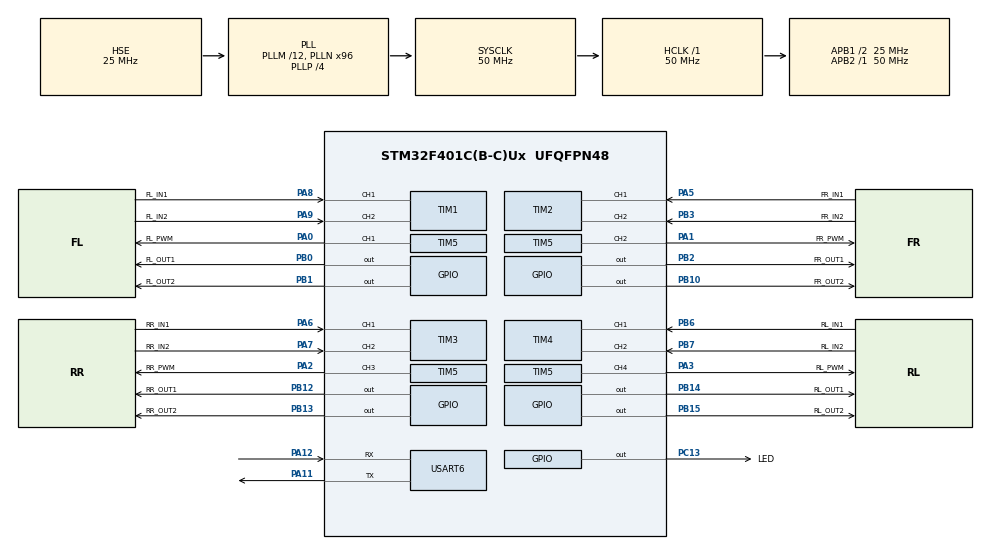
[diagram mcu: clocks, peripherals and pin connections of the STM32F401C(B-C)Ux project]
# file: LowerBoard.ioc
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Dma.Request0=USART6_RX
Dma.Request1=USART6_TX
Dma.USART6_RX.0.Direction=DMA_PERIPH_TO_MEMORY
Dma.USART6_RX.0.FIFOMode=DMA_FIFOMODE_DISABLE
Dma.USART6_RX.0.Instance=DMA2_Stream1
Dma.USART6_RX.0.MemDataAlignment=DMA_MDATAALIGN_BYTE
Dma.USART6_RX.0.MemInc=DMA_MINC_ENABLE
Dma.USART6_RX.0.Mode=DMA_NORMAL
Dma.USART6_RX.0.PeriphDataAlignment=DMA_PDATAALIGN_BYTE
Dma.USART6_RX.0.PeriphInc=DMA_PINC_DISABLE
Dma.USART6_RX.0.Priority=DMA_PRIORITY_LOW
Dma.USART6_TX.1.Direction=DMA_MEMORY_TO_PERIPH
Dma.USART6_TX.1.FIFOMode=DMA_FIFOMODE_DISABLE
Dma.USART6_TX.1.Instance=DMA2_Stream6
Dma.USART6_TX.1.MemDataAlignment=DMA_MDATAALIGN_BYTE
Dma.USART6_TX.1.MemInc=DMA_MINC_ENABLE
Dma.USART6_TX.1.Mode=DMA_NORMAL
Dma.USART6_TX.1.PeriphDataAlignment=DMA_PDATAALIGN_BYTE
Dma.USART6_TX.1.PeriphInc=DMA_PINC_DISABLE
Dma.USART6_TX.1.Priority=DMA_PRIORITY_LOW
Mcu.Family=STM32F4
Mcu.Name=STM32F401C(B-C)Ux
Mcu.Package=UFQFPN48
NVIC.DMA2_Stream1_IRQn=true\:0\:0\:false\:false\:true\:false\:true\:true
NVIC.DMA2_Stream6_IRQn=true\:0\:0\:false\:false\:true\:false\:true\:true
NVIC.PriorityGroup=NVIC_PRIORITYGROUP_4
NVIC.TIM1_TRG_COM_TIM11_IRQn=true\:0\:0\:false\:false\:true\:true\:true\:true
NVIC.TIM1_UP_TIM10_IRQn=true\:0\:0\:false\:false\:true\:true\:true\:true
NVIC.USART6_IRQn=true\:0\:0\:false\:false\:true\:false\:true\:true
PA0-WKUP.GPIO_Label=FL_PWM
PA0-WKUP.GPIO_Speed=GPIO_SPEED_FREQ_HIGH
PA0-WKUP.Signal=S_TIM5_CH1
PA1.GPIO_Label=FR_PWM
PA1.GPIO_Speed=GPIO_SPEED_FREQ_HIGH
PA1.Signal=S_TIM5_CH2
PA11.Mode=Asynchronous
PA11.Signal=USART6_TX
PA12.Mode=Asynchronous
PA12.Signal=USART6_RX
PA13.Mode=Serial_Wire
PA13.Signal=SYS_JTMS-SWDIO
PA14.Mode=Serial_Wire
PA14.Signal=SYS_JTCK-SWCLK
PA2.GPIO_Label=RR_PWM
PA2.GPIO_Speed=GPIO_SPEED_FREQ_HIGH
PA2.Signal=S_TIM5_CH3
PA3.GPIO_Label=RL_PWM
PA3.GPIO_Speed=GPIO_SPEED_FREQ_HIGH
PA3.Signal=S_TIM5_CH4
PA5.GPIO_Label=FR_IN1
PA5.GPIO_PuPd=GPIO_NOPULL
PA5.Signal=S_TIM2_CH1_ETR
PA6.GPIO_Label=RR_IN1
PA6.GPIO_PuPd=GPIO_NOPULL
PA6.Signal=S_TIM3_CH1
PA7.GPIO_Label=RR_IN2
PA7.GPIO_PuPd=GPIO_NOPULL
PA7.Signal=S_TIM3_CH2
PA8.GPIO_Label=FL_IN1
PA8.GPIO_PuPd=GPIO_NOPULL
PA8.Signal=S_TIM1_CH1
PA9.GPIO_Label=FL_IN2
PA9.GPIO_PuPd=GPIO_NOPULL
PA9.Signal=S_TIM1_CH2
PB0.GPIO_Label=FL_OUT1
PB0.Signal=GPIO_Output
PB1.GPIO_Label=FL_OUT2
PB1.Signal=GPIO_Output
PB10.GPIO_Label=FR_OUT2
PB10.Signal=GPIO_Output
PB12.GPIO_Label=RR_OUT1
PB12.Signal=GPIO_Output
PB13.GPIO_Label=RR_OUT2
PB13.Signal=GPIO_Output
PB14.GPIO_Label=RL_OUT1
PB14.Signal=GPIO_Output
PB15.GPIO_Label=RL_OUT2
PB15.Signal=GPIO_Output
PB2.GPIO_Label=FR_OUT1
PB2.Signal=GPIO_Output
PB3.GPIO_Label=FR_IN2
PB3.Signal=S_TIM2_CH2
PB6.GPIO_Label=RL_IN1
PB6.Signal=S_TIM4_CH1
PB7.GPIO_Label=RL_IN2
PB7.Signal=S_TIM4_CH2
PC13-ANTI_TAMP.GPIO_Label=LED
PC13-ANTI_TAMP.GPIO_PuPd=GPIO_NOPULL
PC13-ANTI_TAMP.PinState=GPIO_PIN_SET
PC13-ANTI_TAMP.Signal=GPIO_Output
PH0\ -\ OSC_IN.Mode=HSE-External-Oscillator
PH0\ -\ OSC_IN.Signal=RCC_OSC_IN
PH1\ -\ OSC_OUT.Mode=HSE-External-Oscillator
PH1\ -\ OSC_OUT.Signal=RCC_OSC_OUT
ProjectManager.HeapSize=0x200
ProjectManager.StackSize=0x400
ProjectManager.TargetToolchain=Makefile
RCC.48MHZClocksFreq_Value=50000000
RCC.AHBFreq_Value=50000000
RCC.APB1CLKDivider=RCC_HCLK_DIV2
RCC.APB1Freq_Value=25000000
RCC.APB1TimFreq_Value=50000000
RCC.APB2Freq_Value=50000000
RCC.APB2TimFreq_Value=50000000
RCC.CortexFreq_Value=50000000
RCC.HCLKFreq_Value=50000000
RCC.HSE_VALUE=25000000
RCC.HSI_VALUE=16000000
RCC.LSE_VALUE=32768
RCC.PLLM=12
RCC.PLLN=96
RCC.PLLP=RCC_PLLP_DIV4
RCC.PLLSourceVirtual=RCC_PLLSOURCE_HSE
RCC.SYSCLKFreq_VALUE=50000000
RCC.SYSCLKSource=RCC_SYSCLKSOURCE_PLLCLK
RCC.VCOOutputFreq_Value=200000000
SH.S_TIM1_CH1.0=TIM1_CH1,Encoder_Interface
SH.S_TIM1_CH2.0=TIM1_CH2,Encoder_Interface
SH.S_TIM2_CH1_ETR.0=TIM2_CH1,Encoder_Interface
SH.S_TIM2_CH2.0=TIM2_CH2,Encoder_Interface
SH.S_TIM3_CH1.0=TIM3_CH1,Encoder_Interface
SH.S_TIM3_CH2.0=TIM3_CH2,Encoder_Interface
SH.S_TIM4_CH1.0=TIM4_CH1,Encoder_Interface
SH.S_TIM4_CH2.0=TIM4_CH2,Encoder_Interface
SH.S_TIM5_CH1.0=TIM5_CH1,PWM Generation1 CH1
SH.S_TIM5_CH2.0=TIM5_CH2,PWM Generation2 CH2
SH.S_TIM5_CH3.0=TIM5_CH3,PWM Generation3 CH3
SH.S_TIM5_CH4.0=TIM5_CH4,PWM Generation4 CH4
TIM1.EncoderMode=TIM_ENCODERMODE_TI12
TIM10.Period=1000-1
TIM10.Prescaler=50-1
TIM11.Period=10000-1
TIM11.Prescaler=50-1
TIM2.EncoderMode=TIM_ENCODERMODE_TI12
TIM3.EncoderMode=TIM_ENCODERMODE_TI12
TIM4.EncoderMode=TIM_ENCODERMODE_TI12
TIM5.Channel-PWM\ Generation1\ CH1=TIM_CHANNEL_1
TIM5.Channel-PWM\ Generation2\ CH2=TIM_CHANNEL_2
TIM5.Channel-PWM\ Generation3\ CH3=TIM_CHANNEL_3
TIM5.Channel-PWM\ Generation4\ CH4=TIM_CHANNEL_4
TIM5.Period=5000-1
TIM5.Prescaler=0
USART6.VirtualMode=VM_ASYNC
VP_CRC_VS_CRC.Mode=CRC_Activate
VP_TIM10_VS_ClockSourceINT.Mode=Enable_Timer
VP_TIM11_VS_ClockSourceINT.Mode=Enable_Timer
board=custom

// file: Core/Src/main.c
/* USER CODE BEGIN Header */
/**
  ******************************************************************************
  * @file           : main.c
  * @brief          : Main program body
  ******************************************************************************
  * @attention
  *
  * Copyright (c) 2026 STMicroelectronics.
  * All rights reserved.
  *
  * This software is licensed under terms that can be found in the LICENSE file
  * in the root directory of this software component.
  * If no LICENSE file comes with this software, it is provided AS-IS.
  *
  ******************************************************************************
  */
/* USER CODE END Header */
#include "main.h"
#include "crc.h"
#include "dma.h"
#include "tim.h"
#include "usart.h"
#include "gpio.h"

/* USER CODE BEGIN Includes */
#include "app/app_test.h"
#include "app/app_under_board_task.h"
/* USER CODE END Includes */

void SystemClock_Config(void);

int main(void)
{

  /* MCU Configuration--------------------------------------------------------*/

  /* Reset of all peripherals, Initializes the Flash interface and the Systick. */
  HAL_Init();

  /* Configure the system clock */
  SystemClock_Config();

  /* Initialize all configured peripherals */
  MX_GPIO_Init();
  MX_DMA_Init();
  MX_TIM1_Init();
  MX_TIM2_Init();
  MX_TIM3_Init();
  MX_TIM4_Init();
  MX_TIM5_Init();
  MX_USART6_UART_Init();
  MX_TIM10_Init();
  MX_TIM11_Init();
  MX_CRC_Init();
  /* USER CODE BEGIN 2 */

  App_UnderBoardTaskInit();
  // App_TestMotorPIDStart();
  // App_TestMotorSequenceStart();
  // App_TestMotorPID70PercentForwardStart();

  /* USER CODE END 2 */

  /* Infinite loop */
  /* USER CODE BEGIN WHILE */
  while (1)
  {
    App_UnderBoardTaskRun();
    // App_TestUpdateChassisTargetRPMDebug();
    // App_TestUpdateChassisTargetRPMDebug();
    /* USER CODE END WHILE */

  }
}

void SystemClock_Config(void)
{
  RCC_OscInitTypeDef RCC_OscInitStruct = {0};
  RCC_ClkInitTypeDef RCC_ClkInitStruct = {0};

  /** Configure the main internal regulator output voltage
  */
  __HAL_RCC_PWR_CLK_ENABLE();
  __HAL_PWR_VOLTAGESCALING_CONFIG(PWR_REGULATOR_VOLTAGE_SCALE2);

  /** Initializes the RCC Oscillators according to the specified parameters
  * in the RCC_OscInitTypeDef structure.
  */
  RCC_OscInitStruct.OscillatorType = RCC_OSCILLATORTYPE_HSE;
  RCC_OscInitStruct.HSEState = RCC_HSE_ON;
  RCC_OscInitStruct.PLL.PLLState = RCC_PLL_ON;
  RCC_OscInitStruct.PLL.PLLSource = RCC_PLLSOURCE_HSE;
  RCC_OscInitStruct.PLL.PLLM = 12;
  RCC_OscInitStruct.PLL.PLLN = 96;
  RCC_OscInitStruct.PLL.PLLP = RCC_PLLP_DIV4;
  RCC_OscInitStruct.PLL.PLLQ = 4;
  if (HAL_RCC_OscConfig(&RCC_OscInitStruct) != HAL_OK)
  {
    Error_Handler();
  }

  /** Initializes the CPU, AHB and APB buses clocks
  */
  RCC_ClkInitStruct.ClockType = RCC_CLOCKTYPE_HCLK|RCC_CLOCKTYPE_SYSCLK
                              |RCC_CLOCKTYPE_PCLK1|RCC_CLOCKTYPE_PCLK2;
  RCC_ClkInitStruct.SYSCLKSource = RCC_SYSCLKSOURCE_PLLCLK;
  RCC_ClkInitStruct.AHBCLKDivider = RCC_SYSCLK_DIV1;
  RCC_ClkInitStruct.APB1CLKDivider = RCC_HCLK_DIV2;
  RCC_ClkInitStruct.APB2CLKDivider = RCC_HCLK_DIV1;

  if (HAL_RCC_ClockConfig(&RCC_ClkInitStruct, FLASH_LATENCY_1) != HAL_OK)
  {
    Error_Handler();
  }
}

void Error_Handler(void)
{
  __disable_irq();
  while (1)
  {
  }
}
